# cyt4bb register map
Vendor: Cypress Semiconductor; Series: cyt4bb; File version: 1.0
CPU: CM7 r0p1, little endian, MPU, FPU, VTOR, 3 interrupt priority bits
Registers are 32-bit, read-write, reset 0x0 unless marked. A register's access mark holds for its fields unless they carry their own. Offsets are from the block's base; [hi:lo] are bit positions; lines under a group give offsets from that group; {n}, {i} and the like mark numbered series.

## FAULT — Fault structures
Base 0x40210000
{0x0+0x100*i} STRUCT[{i}] (i=0..3) group — Fault structure
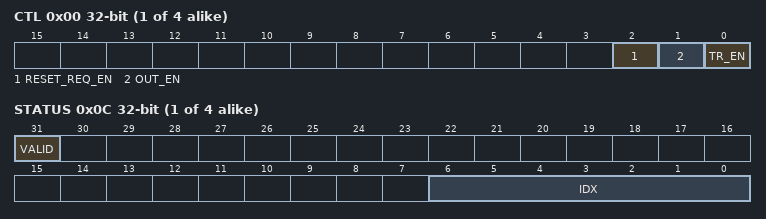
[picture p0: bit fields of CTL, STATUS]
  0x00 CTL — Fault control
    [2] RESET_REQ_EN — Reset request enable: '0': Disabled. '1': Enabled. The output reset request signal 'fault_reset_req' reflects STATUS.VALID. This reset causes a warm/soft/core reset. This warm/soft/core reset does not affect the fault logic STATUS, DATA0, ..., DATA3 registers (allowing for post soft reset failure analysis). The 'fault_reset_req' signals of the individual fault report structures are combined (logically OR'd) into a single SRSS 'fault_reset_req' signal.
    [1] OUT_EN — IO output signal enable: '0': Disabled. The IO output signal 'fault_out' is '0'. The IO output enable signal 'fault_out_en' is '0'. '1': Enabled. The IO output signal 'fault_out' reflects STATUS.VALID. The IO output enable signal 'fault_out_en' is '1'.
    [0] TR_EN — Trigger output enable: '0': Disabled. The trigger output 'tr_fault' is '0'. '1': Enabled. The trigger output 'tr_fault' reflects STATUS.VALID. The trigger can be used to initiate a Datawire transfer of the FAULT data (FAULT_DATA0 through FAULT_DATA3).
  0x0C STATUS (reset mask 0x80000000) — Fault status
    [31] VALID — Valid indication: '0': Invalid. '1': Valid. STATUS.IDX, DATA0, ..., DATA3 specify the fault. Note: Typically, HW sets this field to '1' (on an activated HW fault source that is 'enabled' by the MASK registers) and SW clears this field to '0' (typically by boot code SW (after a warm system reset, when the fault is handled). In this typical use case scenario, the HW source fault data is simultaneously captured into DATA0, ..., DATA3 when the VALID field is set to '1'. An exceptional SW use case scenario is identified as well. In this scenario, SW sets this field to '1' with a fault source index different to one of the defined HW fault sources. SW update is not restricted by the MASK registers). In both use case scenarios, the following holds: - STATUS.IDX, DATA0, ..., DATA3 can only be written when STATUS.VALID is '0'; the fault structure is not in use yet. Writing STATUS.VALID to '1' effectively locks the fault structure (until SW clears STATUS.VALID to '0'). This restriction requires a SW update to sequentially update the DATA registers followed by an update of the STATUS register. Note: For the exceptional SW use case, sequential updates to the DATA and STATUS registers may be 'interrupted' by a HW fault capture. In this case, the SW DATA register updates are overwritten by the HW update (and the STATUS.IDX field will reflect the HW capture)
    [6:0] IDX — The fault source index for which fault information is captured in DATA0 through DATA3. The fault information is fault source specific and described below. Note: this register field (and associated fault source data in DATA0 through DATA3) should only be considered valid, when VALID is '1'.
      0=MPU_0 (Bus master 0 MPU/SMPU. DATA0[31:0]: Violating address. DATA1[0]: User read. DATA1[1]: User write. DATA1[2]: User execute. DATA1[3]: Privileged read. DATA1[4]: Privileged write. DATA1[5]: Privileged execute. DATA1[6]: Non-secure. DATA1[11:8]: Master identifier. DATA1[15:12]: Protection context identifier. DATA1[31]: '0' MPU violation; '1': SMPU violation.); {v}=MPU_{v} (Bus master {v} MPU. See MPU_0 description.) (v=1..15); 16=CM7_1_TCM_C_ECC (Correctable ECC error in CM7_1 TCM memory. See CM7_0_TCM_C_ECC description.); 17=CM7_1_TCM_NC_ECC (Non Correctable ECC error in CM7_1 TCM memory. See CM7_0_TCM_C_ECC description.); 18=CM7_0_CACHE_C_ECC (Correctable ECC error in CM7_0 Cache memories DATA0[16:2]: location information: Tag/Data SRAM, Way, Index and line Offset, see CM7 UGRM IEBR0/DEBR0 description for details. DATA0[31]: 0=Instruction cache, 1= Data cache); 19=CM7_0_CACHE_NC_ECC (Non Correctable ECC error in CM7_0 Cache memories. See CM7_0_CACHE_C_ECC description); 20=CM7_1_CACHE_C_ECC (Correctable ECC error in CM7_1 Cache memories. See CM7_0_CACHE_C_ECC description.); 21=CM7_1_CACHE_NC_ECC (Non Correctable ECC error in CM7_1 Cache memories. See CM7_0_CACHE_C_ECC description.); 25=MS_PPU_4 (Peripheral interconnect, master interface 4 PPU. See MS_PPU_0 description.); 26=PERI_ECC (Peripheral interconnect, protection structures SRAM, correctable ECC error: DATA0[10:0]: Violating address. DATA1[7:0]: Syndrome of SRAM word.); 27=PERI_NC_ECC (Peripheral interconnect, protection structures SRAM, non-correctable ECC error.); 28=MS_PPU_0 (Peripheral interconnect, master interface 0 PPU. DATA0[31:0]: Violating address. DATA1[0]: User read. DATA1[1]: User write. DATA1[2]: User execute. DATA1[3]: Privileged read. DATA1[4]: Privileged write. DATA1[5]: Privileged execute. DATA1[6]: Non-secure. DATA1[11:8]: Master identifier. DATA1[15:12]: Protection context identifier. DATA1[31:28]: '0': master interface, PPU violation, '1': timeout detected, '2': bus error, other: undefined.); 29=MS_PPU_1 (Peripheral interconnect, master interface 1 PPU. See MS_PPU_0 description.); 30=MS_PPU_2 (Peripheral interconnect, master interface 2 PPU. See MS_PPU_0 description.); 31=MS_PPU_3 (Peripheral interconnect, master interface 3 PPU. See MS_PPU_0 description.); 32=GROUP_FAULT_0 (Peripheral group 0 fault detection. DATA0[31:0]: Violating address. DATA1[0]: User read. DATA1[1]: User write. DATA1[2]: User execute. DATA1[3]: Privileged read. DATA1[4]: Privileged write. DATA1[5]: Privileged execute. DATA1[6]: Non-secure. DATA1[11:8]: Master identifier. DATA1[15:12]: Protection context identifier. DATA1[31:28]: '0': decoder or peripheral bus error, other: undefined.); {v}=GROUP_FAULT_{v-32} (Peripheral group {v-32} fault detection. See GROUP_FAULT_0 description.) (v=33..47); 48=FLASHC_MAIN_BUS_ERROR (Flash controller, main interface, bus error: FAULT_DATA0[26:0]: Violating address. Append 5'b00010 as most significant bits to derive 32-bit system address. FAULT_DATA1[11:8]: Master identifier.); 49=FLASHC_MAIN_C_ECC (Flash controller, main interface, correctable ECC error: DATA[26:0]: Violating address. Append 5'b00010 as most significant bits to derive 32-bit system address. DATA1[7:0]: Syndrome of 64-bit word (at address offset 0x00). DATA1[15:8]: Syndrome of 64-bit word (at address offset 0x08). DATA1[23:16]: Syndrome of 64-bit word (at address offset 0x10). DATA1[31:24]: Syndrome of 64-bit word (at address offset 0x18).); 50=FLASHC_MAIN_NC_ECC (Flash controller, main interface, non-correctable ECC error. See FLASHC_MAIN_C_ECC description.); 51=FLASHC_WORK_BUS_ERROR (Flash controller, work interface, bus error. See FLASHC_MAIN_BUS_ERROR description.); 52=FLASHC_WORK_C_ECC (Flash controller, work interface, correctable ECC error: DATA0[26:0]: Violating address. Append 5'b00010 as most significant bits to derive 32-bit system address. DATA1[6:0]: Syndrome of 32-bit word.); 53=FLASHC_WORK_NC_ECC (Flash controller, work interface, non-correctable ECC error. See FLASHC_WORK_C_ECC description.); 54=FLASHC_CM0_CA_C_ECC (Flash controller, CM0+ cache, correctable ECC error: DATA0[26:0]: Violating address. DATA1[6:0]: Syndrome of 32-bit SRAM word (at address offset 0x0). DATA1[14:8]: Syndrome of 32-bit SRAM word (at address offset 0x4). DATA1[22:16]: Syndrome of 32-bit SRAM word (at address offset 0x8). DATA1[30:24]: Syndrome of 32-bit SRAM word (at address offset 0xc).); 55=FLASHC_CM0_CA_NC_ECC (Flash controller, CM0+ cache, non-correctable ECC error. See FLASHC_CM0_CA_C_ECC description.); 56=CM7_0_TCM_C_ECC (Correctable ECC error in CM7_0 TCM memory DATA0[23:2]: Violating address. DATA1[7:0]: Syndrome of code word (at address offset 0x0). DATA1[31:30]: 0= ITCM, 2=D0TCM, 3=D1TCM); 57=CM7_0_TCM_NC_ECC (Non Correctable ECC error in CM7_0 TCM memory. See CM7_0_TCM_C_ECC description.); 58=RAMC0_C_ECC (System SRAM 0 correctable ECC error: DATA0[31:0]: Violating address. DATA1[6:0]: Syndrome of 32-bit SRAM code word.); 59=RAMC0_NC_ECC (System SRAM 0 non-correctable ECC error. See RAMC0_C_ECC description.); 60=RAMC1_C_ECC (System SRAM 1 correctable ECC error. See RAMC0_C_ECC description.); 61=RAMC1_NC_ECC (System SRAM 1 non-correctable ECC error. See RAMC0_C_ECC description.); 62=RAMC2_C_ECC (System SRAM 2 correctable ECC error. See RAMC0_C_ECC description.); 63=RAMC2_NC_ECC (System SRAM 2 non-correctable ECC error. See RAMC0_C_ECC description.); 64=CRYPTO_C_ECC (Cryptography SRAM correctable ECC error. DATA0[31:0]: Violating address. DATA1[6:0]: Syndrome of Least Significant 32-bit SRAM. DATA1[14:8]: Syndrome of Most Significant 32-bit SRAM.); 65=CRYPTO_NC_ECC (Cryptography SRAM non-correctable ECC error. See CRYPTO_C_ECC description.); 70=DW0_C_ECC (DataWire 0 SRAM 1 correctable ECC error: DATA0[11:0]: Violating DW SRAM address (word address, assuming byte addressable). DATA1[6:0]: Syndrome of 32-bit SRAM code word.); 71=DW0_NC_ECC (DataWire 0 SRAM 1 non-correctable ECC error. See DW0_C_ECC description.); 72=DW1_C_ECC (DataWire 1 SRAM 1 correctable ECC error. See DW0_C_ECC description.); 73=DW1_NC_ECC (DataWire 1 SRAM 1 non-correctable ECC error. See DW0_C_ECC description.); 74=FM_SRAM_C_ECC (eCT Flash SRAM (for embedded operations) correctable ECC error: DATA0[15:0]: Address location in the eCT Flash SRAM. DATA1[6:0]: Syndrome of 32-bit SRAM word.); 75=FM_SRAM_NC_ECC (eCT Flash SRAM non-correctable ECC error: See FM_SRAM_C_ECC description.); 80=CAN0_C_ECC (CAN controller 0 MRAM correctable ECC error: DATA0[15:0]: Violating address. DATA0[22:16]: ECC violating data[38:32] from MRAM. DATA0[27:24]: Master ID: 0-7 = CAN channel ID within mxttcanfd cluster, 8 = AHB I/F DATA1[31:0]: ECC violating data[31:0] from MRAM.); 81=CAN0_NC_ECC (CAN controller 0 MRAM non-correctable ECC error: DATA0[15:0]: Violating address. DATA0[22:16]: ECC violating data[38:32] from MRAM (not for Address Error). DATA0[27:24]: Master ID: 0-7 = CAN channel ID within mxttcanfd cluster, 8 = AHB I/F DATA0[30]: Write access, only possible for Address Error DATA0[31]: Address Error: a CAN channel did an MRAM access above MRAM_SIZE DATA1[31:0]: ECC violating data[31:0] from MRAM (not for Address Error).); 82=CAN1_C_ECC (CAN controller 1 MRAM correctable ECC error. See CAN0_C_ECC description.); 83=CAN1_NC_ECC (CAN controller 1 MRAM non-correctable ECC error. See CAN0_NC_ECC description.); 84=VIDEOSS_VRPU0 (Video Ram Protection Unit 0 fault detection. DATA0[31:0]: Violating address. DATA1[0]: User read. DATA1[1]: User write. DATA1[2]: User execute. DATA1[3]: Privileged read. DATA1[4]: Privileged write. DATA1[5]: Privileged execute. DATA1[6]: Non-secure. DATA1[11:8]: Master identifier. DATA1[15:12]: Protection context identifier. DATA1[31:28]: '0': decoder or peripheral bus error, other: undefined.); {v}=VIDEOSS_VRPU{v-84} (Video Ram Protection Unit {v-84} fault detection. See VIDEOSS_VRPU0 description.) (v=85..89); 90=SRSS_CSV (SRSS Clock SuperVisor (CSV) violation detected. Multiple CSV can detect a violation at the same time. DATA0[15:0]: clk_hf* root CSV violation flags. DATA0[24]: clk_ref CSV violation flag (reference clock for clk_hf CSVs) DATA0[25]: clk_lf CSV violation flag DATA0[26]: clk_hvilo CSV violation flag); 91=SRSS_SSV (SRSS Clock SuperVisor (CSV) violation detected. Multiple CSV can detect a violation at the same time. DATA0[0]: BOD on VDDA DATA[1]: OVD on VDDA DATA[16]: LVD/HVD #1 DATA0[17]: LVD/HVD #2); 92=SRSS_MCWDT0 (SRSS Multi-Counter Watch Dog Timer (MCWDT) #0 violation detected. Multiple counters can detect a violation at the same time. DATA0[0]: MCWDT subcounter 0 LOWER_LIMIT DATA0[1]: MCWDT subcounter 0 UPPER_LIMIT DATA0[2]: MCWDT subcounter 1 LOWER_LIMIT DATA0[3]: MCWDT subcounter 1 UPPER_LIMIT); 93=SRSS_MCWDT1 (SRSS Multi-Counter Watch Dog Timer (MCWDT) #1 violation detected. See SRSS_MCWDT0 description.); 94=SRSS_MCWDT2 (SRSS Multi-Counter Watch Dog Timer (MCWDT) #2 violation detected. See SRSS_MCWDT0 description.); 95=SRSS_MCWDT3 (SRSS Multi-Counter Watch Dog Timer (MCWDT) #3 violation detected. See SRSS_MCWDT0 description.)
  {0x10+4j} DATA[{j}] (j=0..3) reset not defined — Fault data
    [31:0] DATA — Captured fault source data. Note: the DATA registers can only be written when STATUS.VALID is '0'. Note: the fault source index STATUS.IDX specifies the format of the DATA registers.
  0x40 PENDING0 ro reset not defined — Fault pending 0
    [31:0] SOURCE — This field specifies the following sources: Bit 0: CM0 MPU. Bit 1: CRYPTO MPU. Bit 2: DW 0 MPU. Bit 3: DW 1 MPU. Bit 4: DMA controller MPU. ... Bit 15: DAP MPU. Bit 16: CM4 system bus MPU. Bit 17: CM4 code bus MPU (for non FLASH controller accesses). Bit 18: CM4 code bus MPU (for FLASH controller accesses).
  0x44 PENDING1 ro reset not defined — Fault pending 1
    [31:0] SOURCE — This field specifies the following sources: Bit 0: Peripheral group 0 PPU. Bit 1: Peripheral group 1 PPU. Bit 2: Peripheral group 2 PPU. Bit 3: Peripheral group 3 PPU. Bit 4: Peripheral group 4 PPU. Bit 5: Peripheral group 5 PPU. Bit 6: Peripheral group 6 PPU. Bit 7: Peripheral group 7 PPU. ... Bit 15: Peripheral group 15 PPU. Bit 16 - 31: See STATUS register.
  0x48 PENDING2 ro reset not defined — Fault pending 2
    [31:0] SOURCE — This field specifies the following sources: Bit 0 - 31: See STATUS register.
  0x50 MASK0 — Fault mask 0
    [31:0] SOURCE — Fault source enables: Bits 31-0: Fault sources 31 to 0.
  0x54 MASK1 — Fault mask 1
    [31:0] SOURCE — Fault source enables: Bits 31-0: Fault sources 63 to 32.
  0x58 MASK2 — Fault mask 2
    [31:0] SOURCE — Fault source enables: Bits 31-0: Fault sources 95 to 64.
  0xC0 INTR — Interrupt
    [0] FAULT — This interrupt cause field is activated (HW sets the field to '1') when an enabled (MASK0/MASK1/MASK2) pending fault source is captured: - STATUS.VALID is set to '1'. - STATUS.IDX specifies the fault source index. - DATA0 through DATA3 captures the fault source data. SW writes a '1' to this field to clear the interrupt cause to '0'. SW clear STATUS.VALID to '0' to enable capture of the next fault. Note that when there is an enabled pending fault source, the pending fault source is captured immediately and INTR.FAULT is immediately activated (set to '1').
  0xC4 INTR_SET — Interrupt set
    [0] FAULT — SW writes a '1' to this field to set the corresponding field in the INTR register.
  0xC8 INTR_MASK — Interrupt mask
    [0] FAULT — Mask bit for corresponding field in the INTR register.
  0xCC INTR_MASKED ro — Interrupt masked
    [0] FAULT — Logical and of corresponding INTR and INTR_MASK fields.

## Notices in the file
Copyright 2016-2019, Cypress Semiconductor Corporation.  All rights reserved.
You may use this file only in accordance with the license, terms, conditions,
disclaimers, and limitations in the end user license agreement accompanying
the software package with which this file was provided.
